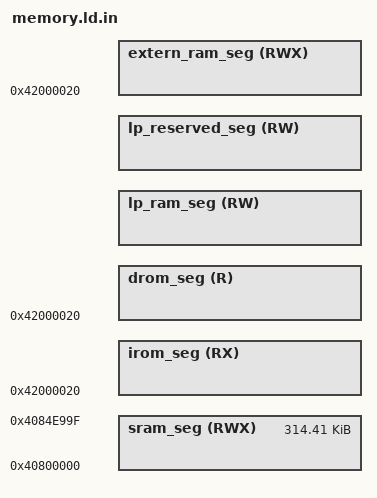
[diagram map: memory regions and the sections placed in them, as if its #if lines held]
/*
 * SPDX-FileCopyrightText: 2022 Espressif Systems (Shanghai) CO LTD
 *
 * SPDX-License-Identifier: Apache-2.0
 */

/**
 *                    ESP32-C5 Linker Script Memory Layout
 * This file describes the memory layout (memory blocks) by virtual memory addresses.
 * This linker script is passed through the C preprocessor to include configuration options.
 * Please use preprocessor features sparingly!
 * Restrict to simple macros with numeric values, and/or #if/#endif blocks.
 */

#include "sdkconfig.h"
#include "ld.common"

#define SRAM_SEG_START     0x40800000
#define SRAM_SEG_END       0x4084E9A0  /* 2nd stage bootloader iram_loader_seg start address */
#define SRAM_SEG_SIZE      SRAM_SEG_END - SRAM_SEG_START

/*
 * IDRAM0_2_SEG_SIZE_DEFAULT is used when page size is 64KB
 */
#define IDRAM0_2_SEG_SIZE   (CONFIG_MMU_PAGE_SIZE << 8)

MEMORY
{
  /**
   *  All these values assume the flash cache is on, and have the blocks this uses subtracted from the length
   *  of the various regions. The 'data access port' dram/drom regions map to the same iram/irom regions but
   *  are connected to the data port of the CPU and eg allow byte-wise access.
   */

#if CONFIG_APP_BUILD_USE_FLASH_SECTIONS
  /* Flash mapped instruction data */
  irom_seg (RX) :                    org = 0x42000020, len = IDRAM0_2_SEG_SIZE - 0x20

  /**
   * (0x20 offset above is a convenience for the app binary image generation.
   * Flash cache has 64KB pages. The .bin file which is flashed to the chip
   * has a 0x18 byte file header, and each segment has a 0x08 byte segment
   * header. Setting this offset makes it simple to meet the flash cache MMU's
   * constraint that (paddr % 64KB == vaddr % 64KB).)
   */
#endif // CONFIG_APP_BUILD_USE_FLASH_SECTIONS

  /**
   * Shared data RAM, excluding memory reserved for ROM bss/data/stack.
   * Enabling Bluetooth & Trace Memory features in menuconfig will decrease the amount of RAM available.
   */
  sram_seg (RWX) :                   org = SRAM_SEG_START, len = SRAM_SEG_SIZE

#if CONFIG_APP_BUILD_USE_FLASH_SECTIONS
  /* Flash mapped constant data */
  drom_seg (R) :                     org = 0x42000020, len = IDRAM0_2_SEG_SIZE - 0x20

  /* (See irom_seg for meaning of 0x20 offset in the above.) */
#endif // CONFIG_APP_BUILD_USE_FLASH_SECTIONS

  /**
   * lp ram memory (RWX). Persists over deep sleep. // TODO: IDF-5667
   */
#if CONFIG_ULP_COPROC_ENABLED
  lp_ram_seg(RW)  :                 org = 0x50000000 + CONFIG_ULP_COPROC_RESERVE_MEM,
                                    len = 0x4000 - CONFIG_ULP_COPROC_RESERVE_MEM - RESERVE_RTC_MEM
#else
  lp_ram_seg(RW)  :                 org = 0x50000000, len = 0x4000 - RESERVE_RTC_MEM
#endif // CONFIG_ULP_COPROC_ENABLED

  /* We reduced the size of lp_ram_seg by RESERVE_RTC_MEM value.
     It reserves the amount of LP memory that we use for this memory segment.
     This segment is intended for keeping:
       - (lower addr) rtc timer data (s_rtc_timer_retain_mem, see esp_clk.c files).
       - (higher addr) bootloader rtc data (s_bootloader_retain_mem, when a Kconfig option is on).
     The aim of this is to keep data that will not be moved around and have a fixed address.
  */
  lp_reserved_seg(RW) :        org = 0x50000000 + 0x4000 - RESERVE_RTC_MEM, len = RESERVE_RTC_MEM

  /* PSRAM seg */
  extern_ram_seg(RWX) :        org = 0x42000020, len = IDRAM0_2_SEG_SIZE - 0x20
}

/* Heap ends at top of sram_seg */
_heap_end = 0x40000000;

_data_seg_org = ORIGIN(rtc_data_seg);

/**
 *  The lines below define location alias for .rtc.data section
 *  C5 has no distinguished LP(RTC) fast and slow memory sections, instead, there is a unified LP_RAM section
 *  Thus, the following region segments are not configurable like on other targets
 */
REGION_ALIAS("rtc_iram_seg", lp_ram_seg );
REGION_ALIAS("rtc_data_seg", rtc_iram_seg );
REGION_ALIAS("rtc_slow_seg", rtc_iram_seg );
REGION_ALIAS("rtc_data_location", rtc_iram_seg );
REGION_ALIAS("rtc_reserved_seg", lp_reserved_seg );

#if CONFIG_APP_BUILD_USE_FLASH_SECTIONS
  REGION_ALIAS("default_code_seg", irom_seg);
#else
  REGION_ALIAS("default_code_seg", sram_seg);
#endif // CONFIG_APP_BUILD_USE_FLASH_SECTIONS

#if CONFIG_APP_BUILD_USE_FLASH_SECTIONS
  REGION_ALIAS("default_rodata_seg", drom_seg);
#else
  REGION_ALIAS("default_rodata_seg", sram_seg);
#endif // CONFIG_APP_BUILD_USE_FLASH_SECTIONS

/**
 *  If rodata default segment is placed in `drom_seg`, then flash's first rodata section must
 *  also be first in the segment.
 */
#if CONFIG_APP_BUILD_USE_FLASH_SECTIONS
  ASSERT(_flash_rodata_dummy_start == ORIGIN(default_rodata_seg),
         ".flash_rodata_dummy section must be placed at the beginning of the rodata segment.")
#endif

#if CONFIG_ESP_SYSTEM_USE_EH_FRAME
    ASSERT ((__eh_frame_end > __eh_frame), "Error: eh_frame size is null!");
    ASSERT ((__eh_frame_hdr_end > __eh_frame_hdr), "Error: eh_frame_hdr size is null!");
#endif
